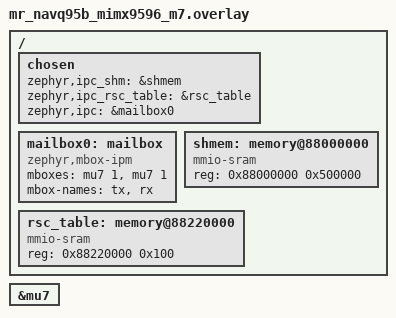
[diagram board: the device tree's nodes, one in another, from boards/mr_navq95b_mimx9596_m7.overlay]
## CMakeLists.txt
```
#
# Copyright 2026 NXP
#
# SPDX-License-Identifier: Apache-2.0
#

cmake_minimum_required(VERSION 3.28.0)
find_package(Zephyr REQUIRED HINTS $ENV{ZEPHYR_BASE})
project(rpmsgfs)

FILE(GLOB app_sources src/*.c)

target_include_directories(app PRIVATE ${LIBMETAL_INCLUDE_DIR} ${OPENAMP_INCLUDE_DIR})
target_compile_definitions(app PRIVATE
  BYPASS_FS_OPEN_FLAGS__CREATE_WITHOUT_RW_IS_NOT_ALLOWED
  BYPASS_FS_OPEN_FLAGS__APPEND_HAS_RW_BY_DEFAULT
  BYPASS_FS_UTIL__SIZE_IN_READDIR_NOT_AVAILABLE
)
target_sources(app PRIVATE
  ${app_sources}
  ../common/test_fs_util.c
  ../common/test_fs_open_flags.c
  ../common/test_fs_dirops.c
  ../common/test_fs_basic.c
  ../common/test_fs_mount_flags.c
  ../common/test_fs_mkfs.c
  ../common/test_fs_gc.c
)
```

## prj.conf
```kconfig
#
# Copyright 2026 NXP
#
# SPDX-License-Identifier: Apache-2.0
#

CONFIG_FILE_SYSTEM=y
CONFIG_FILE_SYSTEM_RPMSGFS=y

CONFIG_HEAP_MEM_POOL_SIZE=2048

CONFIG_ZTEST=y
CONFIG_ZTEST_STACK_SIZE=4096
```

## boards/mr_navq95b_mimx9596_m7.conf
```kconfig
#
# Copyright 2026 NXP
#
# SPDX-License-Identifier: Apache-2.0
#

CONFIG_OPENAMP_WITH_DCACHE=y
CONFIG_UART_CONSOLE=y
CONFIG_ARM_SCMI=y
CONFIG_IPM=y
CONFIG_IPM_MBOX=y
CONFIG_MBOX_NXP_IMX_MU=y
CONFIG_MBOX_INIT_PRIORITY=0
CONFIG_OPENAMP_RSC_TABLE=y
CONFIG_OPENAMP_COPY_RSC_TABLE=y

CONFIG_OPENAMP=y
CONFIG_OPENAMP_RSC_TABLE_NUM_RPMSG_BUFF=8
CONFIG_OPENAMP_RSC_TABLE=y
CONFIG_OPENAMP_MASTER=n
```

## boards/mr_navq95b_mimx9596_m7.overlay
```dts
/*
 * Copyright (c) 2026 NXP
 *
 * SPDX-License-Identifier: Apache-2.0
 */

/ {
	chosen {
		/*
		 * shared memory reserved for the inter-processor communication
		 */
		zephyr,ipc_shm = &shmem;
		zephyr,ipc_rsc_table = &rsc_table;
		zephyr,ipc = &mailbox0;
	};

	mailbox0: mailbox {
		compatible = "zephyr,mbox-ipm";
		mboxes = <&mu7 1>, <&mu7 1>;
		mbox-names = "tx", "rx";
		status = "okay";
	};

	shmem: memory@88000000 {
		compatible = "mmio-sram";
		reg = <0x88000000 0x500000>;
	};

	rsc_table: memory@88220000 {
		compatible = "mmio-sram";
		reg = <0x88220000 0x100>;
	};
};

&mu7 {
	status = "okay";
};
```

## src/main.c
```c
/*
 * Copyright (c) 2026 NXP
 *
 * SPDX-License-Identifier: Apache-2.0
 */

#include <zephyr/ztest.h>
#include <zephyr/fs/fs.h>
#include <zephyr/fs/rpmsgfs.h>
#include <stdlib.h>
#include <string.h>
#include <zephyr/drivers/ipm.h>
#include <openamp/open_amp.h>
#include <resource_table.h>

/* Constants derived from device tree */
#define SHM_NODE       DT_CHOSEN(zephyr_ipc_shm)
#define SHM_START_ADDR DT_REG_ADDR(SHM_NODE)
#define SHM_SIZE       DT_REG_SIZE(SHM_NODE)

#define APP_TASK_STACK_SIZE (1024)
#define MNG_THREAD_PRIORITY 1

K_THREAD_STACK_DEFINE(thread_mng_stack, APP_TASK_STACK_SIZE);

/* All tests must use this structure to mount file system. After each test this structure is cleaned
 * to allow for running next tests unaffected by previous one.
 */
struct fs_mount_t testfs_mnt = {
	.type = FS_RPMSGFS,
	.mnt_point = "/sml",
	.fs_data = "/test",
	.storage_dev = NULL,
	.flags = 0,
};

static struct k_thread thread_mng_data;

static const struct device *const ipm_handle = DEVICE_DT_GET(DT_CHOSEN(zephyr_ipc));

static metal_phys_addr_t shm_physmap = SHM_START_ADDR;
static metal_phys_addr_t rsc_tab_physmap;

static struct metal_io_region shm_io_data; /* shared memory */
static struct metal_io_region rsc_io_data; /* rsc_table memory */

struct rpmsg_rcv_msg {
	void *data;
	size_t len;
};

static struct metal_io_region *shm_io = &shm_io_data;

static struct metal_io_region *rsc_io = &rsc_io_data;
static struct rpmsg_virtio_device rvdev;

static void *rsc_table;
static struct rpmsg_device *rpdev;

static K_SEM_DEFINE(data_sem, 0, 1);
static K_SEM_DEFINE(rpdev_sem, 0, 1);

static void platform_ipm_callback(const struct device *dev, void *context, uint32_t id,
				  volatile void *data)
{
	k_sem_give(&data_sem);
}

static void new_service_cb(struct rpmsg_device *rdev, const char *name, uint32_t src)
{
	TC_PRINT("%s: unexpected ns service receive for name %s\n", __func__, name);
}

static int mailbox_notify(void *priv, uint32_t id)
{
	ARG_UNUSED(priv);

	ipm_send(ipm_handle, 0, id, NULL, 0);
	return 0;
}

static int platform_init(void)
{
	int status;

	/* setup IPM */
	if (!device_is_ready(ipm_handle)) {
		TC_PRINT("IPM device is not ready\n");
		return -1;
	}

	ipm_register_callback(ipm_handle, platform_ipm_callback, NULL);

	status = ipm_set_enabled(ipm_handle, 1);
	if (status) {
		TC_PRINT("ipm_set_enabled failed\n");
		return -1;
	}

	return 0;
}

struct rpmsg_device *platform_create_rpmsg_vdev(unsigned int vdev_index, unsigned int role,
						void (*rst_cb)(struct virtio_device *vdev),
						rpmsg_ns_bind_cb ns_cb)
{
	struct fw_rsc_vdev_vring *vring_rsc;
	struct virtio_device *vdev;
	int ret;

	vdev = rproc_virtio_create_vdev(VIRTIO_DEV_DEVICE, VDEV_ID, rsc_table_to_vdev(rsc_table),
					rsc_io, NULL, mailbox_notify, NULL);

	if (!vdev) {
		TC_PRINT("failed to create vdev\n");
		return NULL;
	}

	/* wait master rpmsg init completion */
	rproc_virtio_wait_remote_ready(vdev);

	vring_rsc = rsc_table_get_vring0(rsc_table);
	ret = rproc_virtio_init_vring(vdev, 0, vring_rsc->notifyid, (void *)vring_rsc->da, rsc_io,
				      vring_rsc->num, vring_rsc->align);
	if (ret) {
		TC_PRINT("failed to init vring 0\n");
		goto failed;
	}

	vring_rsc = rsc_table_get_vring1(rsc_table);
	ret = rproc_virtio_init_vring(vdev, 1, vring_rsc->notifyid, (void *)vring_rsc->da, rsc_io,
				      vring_rsc->num, vring_rsc->align);
	if (ret) {
		TC_PRINT("failed to init vring 1\n");
		goto failed;
	}

	ret = rpmsg_init_vdev(&rvdev, vdev, ns_cb, shm_io, NULL);
	if (ret) {
		TC_PRINT("failed rpmsg_init_vdev\n");
		goto failed;
	}

	return rpmsg_virtio_get_rpmsg_device(&rvdev);

failed:
	rproc_virtio_remove_vdev(vdev);

	return NULL;
}

void rpmsg_rpdev_wait(void)
{
	if (!rpdev) {
		k_sem_take(&rpdev_sem, K_FOREVER);
	}
}

void rpmsg_mng_task(void *arg1, void *arg2, void *arg3)
{
	ARG_UNUSED(arg1);
	ARG_UNUSED(arg2);
	ARG_UNUSED(arg3);

	rpdev = platform_create_rpmsg_vdev(0, VIRTIO_DEV_DEVICE, NULL, new_service_cb);
	if (!rpdev) {
		TC_PRINT("Failed to create rpmsg virtio device\n");
		return;
	}

	rpmsgfs_init_rpmsg(rpdev);

	k_sem_give(&rpdev_sem);

	while (1) {
		int status = k_sem_take(&data_sem, K_FOREVER);

		if (status == 0) {
			rproc_virtio_notified(rvdev.vdev, VRING1_ID);
		}
	}
}

static int init_metal_and_rsc(void)
{
	int rsc_size;
	struct metal_init_params metal_params = METAL_INIT_DEFAULTS;
	int status;

	status = metal_init(&metal_params);
	if (status) {
		TC_PRINT("metal_init: failed: %d\n", status);
		return -1;
	}

	/* declare shared memory region */
	metal_io_init(shm_io, (void *)SHM_START_ADDR, &shm_physmap, SHM_SIZE, -1, 0, NULL);

	/* declare resource table region */
	rsc_table_get(&rsc_table, &rsc_size);
	rsc_tab_physmap = (uintptr_t)rsc_table;

	metal_io_init(rsc_io, rsc_table, &rsc_tab_physmap, rsc_size, -1, 0, NULL);

	return 0;
}

static int init_rpmsg(void)
{
	/* Initialize platform */
	int ret = platform_init();

	if (ret) {
		TC_PRINT("Failed to initialize platform\n");
		return -1;
	}

	TC_PRINT("Starting rpmsg mng thread\n");
	k_tid_t tid = k_thread_create(&thread_mng_data, thread_mng_stack, APP_TASK_STACK_SIZE,
				      rpmsg_mng_task, NULL, NULL, NULL, MNG_THREAD_PRIORITY, 0,
				      K_FOREVER);
	k_thread_start(tid);

	return 0;
};

static void *reset(void)
{
	init_rpmsg();
	rpmsg_rpdev_wait();
	return NULL;
}

static void before_test(void *f)
{
	ARG_UNUSED(f);

	testfs_mnt.flags = 0;
}

static void after_test(void *f)
{
	ARG_UNUSED(f);

	/* Unmount file system */
	fs_unmount(&testfs_mnt);
}

ZTEST_SUITE(rpmsgfs, NULL, reset, before_test, after_test, NULL);
SYS_INIT(init_metal_and_rsc, PRE_KERNEL_1, 0);
```

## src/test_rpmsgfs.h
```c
/*
 * Copyright (c) 2026 NXP
 *
 * SPDX-License-Identifier: Apache-2.0
 */

extern struct fs_mount_t testfs_mnt;

int delete_dir_recursive(const char *path);
```

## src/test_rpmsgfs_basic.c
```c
/*
 * Copyright (c) 2026 NXP
 *
 * SPDX-License-Identifier: Apache-2.0
 */

#include <zephyr/ztest.h>
#include <zephyr/fs/fs.h>
#include "test_rpmsgfs.h"

void test_fs_basic(void);

/* Expected by test_fs_basic() */
struct fs_mount_t *fs_basic_test_mp = &testfs_mnt;

ZTEST(rpmsgfs, test_basic)
{
	zassert_equal(fs_mount(fs_basic_test_mp), 0, "mount failed");

	zassert_equal(delete_dir_recursive(fs_basic_test_mp->mnt_point), 0, "wiping mount failed");

	zassert_equal(fs_unmount(fs_basic_test_mp), 0, "mount failed");

	/* Common basic tests.
	 * (File system is mounted and unmounted during that test.)
	 */
	test_fs_basic();
}
```

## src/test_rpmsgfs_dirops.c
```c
/*
 * Copyright (c) 2026 NXP
 *
 * SPDX-License-Identifier: Apache-2.0
 */

#include <string.h>
#include <zephyr/ztest.h>
#include <zephyr/fs/fs.h>
#include "test_rpmsgfs.h"

/* Mount structure needed by test_fs_basic tests. */
struct fs_mount_t *fs_dirops_test_mp = &testfs_mnt;

void test_fs_dirops(void);

ZTEST(rpmsgfs, test_dirops)
{
	zassert_equal(fs_mount(fs_dirops_test_mp), 0, "mount failed");

	zassert_equal(delete_dir_recursive(fs_dirops_test_mp->mnt_point), 0, "wiping mount failed");

	zassert_equal(fs_unmount(fs_dirops_test_mp), 0, "unmount failed");

	/* Common dirops tests.
	 * (File system is mounted and unmounted during that test.)
	 */
	test_fs_dirops();
}
```

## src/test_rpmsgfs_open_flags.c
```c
/*
 * Copyright (c) 2026 NXP
 *
 * SPDX-License-Identifier: Apache-2.0
 */

#include <zephyr/ztest.h>
#include <zephyr/fs/fs.h>
#include "test_rpmsgfs.h"

void test_fs_open_flags(void);
/* Expected by test_fs_open_flags() */
const char *test_fs_open_flags_file_path = "/sml/the_file";

ZTEST(rpmsgfs, test_fs_open_flags)
{
	struct fs_mount_t *mp = &testfs_mnt;

	zassert_equal(fs_mount(mp), 0, "mount failed");

	test_fs_open_flags();
}
```

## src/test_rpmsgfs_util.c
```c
/*
 * Copyright (c) 2026 NXP
 *
 * SPDX-License-Identifier: Apache-2.0
 */

#include <stdio.h>
#include <zephyr/fs/fs.h>

int delete_dir_recursive(const char *path)
{
	struct fs_dir_t dir;
	struct fs_dirent entry;
	char full_path[MAX_FILE_NAME + 2];

	fs_dir_t_init(&dir);

	int rc = fs_opendir(&dir, path);

	if (rc < 0) {
		return rc;
	}

	while (true) {
		rc = fs_readdir(&dir, &entry);
		if (rc < 0) {
			break;
		}

		if (entry.name[0] == 0) {
			/* End of directory */
			break;
		}

		snprintf(full_path, sizeof(full_path), "%s/%s", path, entry.name);

		if (entry.type == FS_DIR_ENTRY_DIR) {
			/* Recursively delete subdirectory */
			rc = delete_dir_recursive(full_path);

			if (rc < 0) {
				break;
			}
		}

		/* Delete file */
		rc = fs_unlink(full_path);

		if (rc < 0) {
			break;
		}
	}

	fs_closedir(&dir);

	return rc;
}
```
